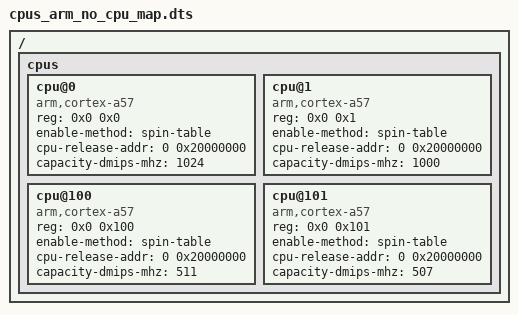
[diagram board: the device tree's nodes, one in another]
// Copyright 2023 The Fuchsia Authors. All rights reserved.
// Use of this source code is governed by a BSD-style license that can be
// found in the LICENSE file.

/dts-v1/;

/ {
    cpus {
        #size-cells = <0>;
        #address-cells = <2>;

        cpu@0 {
            device_type = "cpu";
            compatible = "arm,cortex-a57";
            reg = <0x0 0x0>;
            enable-method = "spin-table";
            cpu-release-addr = <0 0x20000000>;
            capacity-dmips-mhz = <1024>;
        };

        cpu@1 {
            device_type = "cpu";
            compatible = "arm,cortex-a57";
            reg = <0x0 0x1>;
            enable-method = "spin-table";
            cpu-release-addr = <0 0x20000000>;
            capacity-dmips-mhz = <1000>;
        };

        cpu@100 {
            device_type = "cpu";
            compatible = "arm,cortex-a57";
            reg = <0x0 0x100>;
            enable-method = "spin-table";
            cpu-release-addr = <0 0x20000000>;
            capacity-dmips-mhz = <511>;
        };

        cpu@101 {
            device_type = "cpu";
            compatible = "arm,cortex-a57";
            reg = <0x0 0x101>;
            enable-method = "spin-table";
            cpu-release-addr = <0 0x20000000>;
            capacity-dmips-mhz = <507>;
        };
    };
};
